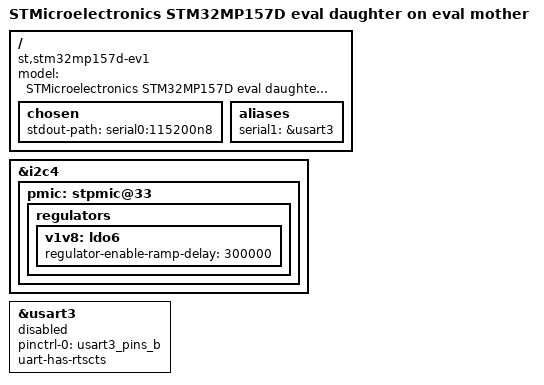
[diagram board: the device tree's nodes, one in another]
// SPDX-License-Identifier: (GPL-2.0+ OR BSD-3-Clause)
/*
 * Copyright (C) STMicroelectronics 2019-2022 - All Rights Reserved
 * Author: Alexandre Torgue <alexandre.torgue@st.com> for STMicroelectronics.
 */

/dts-v1/;

#include <dt-bindings/clock/stm32mp1-clksrc.h>
#include <dt-bindings/mfd/st,stpmic1.h>
#include <dt-bindings/soc/stm32mp15-etzpc.h>

#include "stm32mp157d-ed1.dts"

/ {
	model = "STMicroelectronics STM32MP157D eval daughter on eval mother";
	compatible = "st,stm32mp157d-ev1", "st,stm32mp157d-ed1", "st,stm32mp157";

	chosen {
		stdout-path = "serial0:115200n8";
	};

	aliases {
		serial1 = &usart3;
	};
};

&i2c4 {
	pmic: stpmic@33 {
		regulators {
			v1v8: ldo6 {
				regulator-enable-ramp-delay = <300000>;
			};
		};
	};
};

&usart3 {
	pinctrl-names = "default";
	pinctrl-0 = <&usart3_pins_b>;
	uart-has-rtscts;
	status = "disabled";
};
